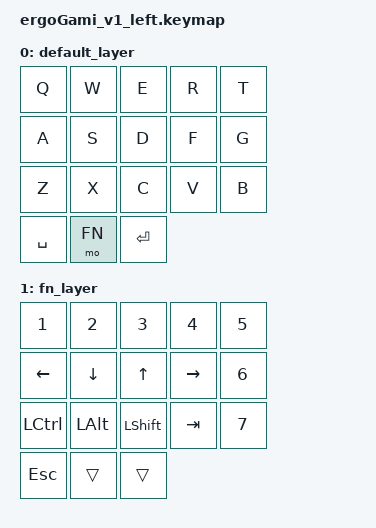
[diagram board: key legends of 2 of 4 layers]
/*
 * Copyright (c) 2022 The ZMK Contributors
 *
 * SPDX-License-Identifier: MIT
 */

#include <dt-bindings/zmk/keys.h>
#include <dt-bindings/zmk/bt.h>
#include <behaviors.dtsi>

/ {
    keymap {
        compatible = "zmk,keymap";

        default_layer {
            bindings = <
                &kp Q     &kp W     &kp E     &kp R     &kp T
                &kp A     &kp S     &kp D     &kp F     &kp G
                &kp Z     &kp X     &kp C     &kp V     &kp B
                &kp SPACE &mo FN    &kp ENTER
            >;
        };

        fn_layer {
            bindings = <
                &kp 1     &kp 2     &kp 3     &kp 4     &kp 5
                &kp LEFT  &kp DOWN  &kp UP    &kp RIGHT &kp 6
                &kp LCTRL &kp LALT  &kp LSHIFT &kp TAB  &kp 7
                &kp ESC   &trans    &trans
            >;
        };

        l3_layer {
            bindings = <
            >;
            display-name = "INT";
        };

        l4_layer {
            bindings = <
            >;
            display-name = "FOO";
        };
    };
};
